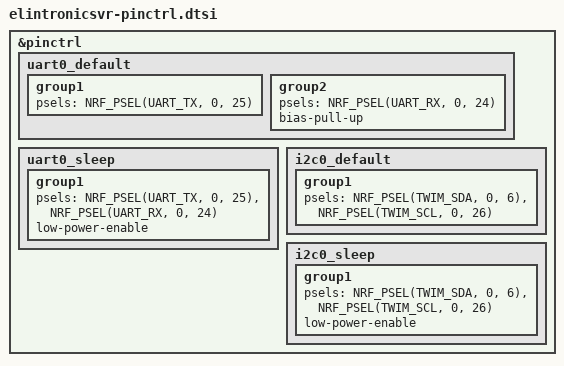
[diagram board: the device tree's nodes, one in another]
&pinctrl {
	uart0_default: uart0_default {
		group1 {
			psels = <NRF_PSEL(UART_TX, 0, 25)>;				
		};
		group2 {
			psels = <NRF_PSEL(UART_RX, 0, 24)>;				
			bias-pull-up;
		};
	};

	uart0_sleep: uart0_sleep {
		group1 {
			psels = <NRF_PSEL(UART_TX, 0, 25)>,
				<NRF_PSEL(UART_RX, 0, 24)>;				
			low-power-enable;
		};
	};

	i2c0_default: i2c0_default {
		group1 {
			psels = <NRF_PSEL(TWIM_SDA, 0, 6)>,
				<NRF_PSEL(TWIM_SCL, 0, 26)>;
		};
	};

	i2c0_sleep: i2c0_sleep {
		group1 {
			psels = <NRF_PSEL(TWIM_SDA, 0, 6)>,
				<NRF_PSEL(TWIM_SCL, 0, 26)>;
			low-power-enable;
		};
	};

};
